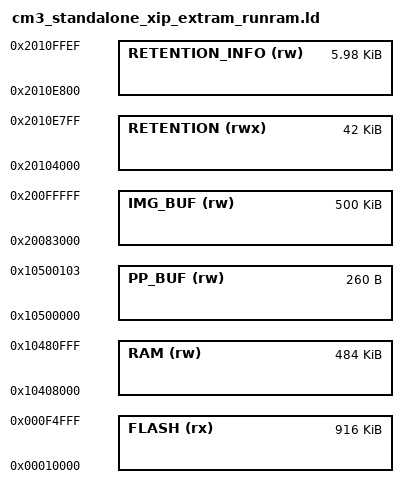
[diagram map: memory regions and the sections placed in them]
MEMORY
{
	FLASH (rx) 	    : ORIGIN = 0x00010000, LENGTH = FLASH_SIZE
	RAM (rw)  	    : ORIGIN = 0x10408000, LENGTH = 492K - STACK_SIZE
	IMG_BUF (rw)  	    : ORIGIN = 0x20083000, LENGTH = 500K
	PP_BUF (rw)  	    : ORIGIN = 0x10500000, LENGTH = 260
	RETENTION (rwx)     : ORIGIN = 0x20104000, LENGTH = 42K
	RETENTION_INFO(rw)  : ORIGIN = 0x2010E800, LENGTH = 6K - UCODE_HDR_SIZE
}
FLASH_SIZE = 916K;
STACK_SIZE = 8K;
UCODE_HDR_SIZE = 16;

INCLUDE ././lib/modem/cm3_common_extram_runram.ld
